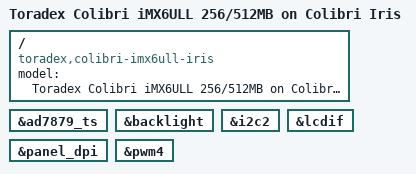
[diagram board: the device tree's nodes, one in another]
// SPDX-License-Identifier: GPL-2.0-or-later OR MIT
/*
 * Copyright 2018-2022 Toradex
 */

/dts-v1/;

#include "imx6ull-colibri-nonwifi.dtsi"
#include "imx6ull-colibri-iris.dtsi"

/ {
	model = "Toradex Colibri iMX6ULL 256/512MB on Colibri Iris";
	compatible = "toradex,colibri-imx6ull-iris",
		     "toradex,colibri-imx6ull",
		     "fsl,imx6ull";
};

&ad7879_ts {
	status = "okay";
};

&backlight {
	status = "okay";
};

&i2c2 {
	status = "okay";
};

&lcdif {
	status = "okay";
};

&panel_dpi {
	status = "okay";
};

&pwm4 {
	status = "okay";
};
